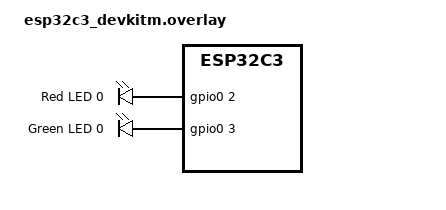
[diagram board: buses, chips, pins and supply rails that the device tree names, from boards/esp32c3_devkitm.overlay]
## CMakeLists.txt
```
# SPDX-License-Identifier: Apache-2.0

cmake_minimum_required(VERSION 3.20.0)

find_package(Zephyr REQUIRED HINTS $ENV{ZEPHYR_BASE})
project(ESP32_Zephyr_WebServer_LED_Control)

target_sources(app PRIVATE src/main.c)

zephyr_linker_sources(SECTIONS sections-rom.ld)
zephyr_linker_section(NAME http_resource_desc_http_service
                      KVMA RAM_REGION GROUP RODATA_REGION)

set(gen_dir ${ZEPHYR_BINARY_DIR}/include/generated/)
set(source_file_index src/root.html)
generate_inc_file_for_target(app ${source_file_index} ${gen_dir}/root.html.gz.inc)
```

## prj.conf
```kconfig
# Wi-Fi Configuration
CONFIG_WIFI=y

# Network Configuration
CONFIG_NET_CONFIG_AUTO_INIT=n
CONFIG_NET_CONNECTION_MANAGER=y
CONFIG_NET_DHCPV4=y
CONFIG_NET_DHCPV4_SERVER=y
CONFIG_NET_IF_MAX_IPV4_COUNT=2
CONFIG_NET_IF_MAX_IPV6_COUNT=2
CONFIG_NET_IPV4=y
CONFIG_NET_L2_ETHERNET=y
CONFIG_NET_L2_WIFI_MGMT=y
CONFIG_NET_MGMT=y
CONFIG_NET_MGMT_EVENT=y
CONFIG_NET_MGMT_EVENT_INFO=y
CONFIG_NET_MGMT_EVENT_QUEUE_SIZE=10
CONFIG_NET_MGMT_EVENT_STACK_SIZE=4096
CONFIG_NET_PKT_RX_COUNT=16
CONFIG_NET_PKT_TX_COUNT=16
CONFIG_NET_SOCKETS_SERVICE_STACK_SIZE=4096
CONFIG_NET_TCP=y
CONFIG_NET_UDP=y
CONFIG_NETWORKING=y

# LOG Configuration
CONFIG_NET_LOG=y
CONFIG_NET_DHCPV4_SERVER_LOG_LEVEL_DBG=y

# HTTP parser
CONFIG_HTTP_SERVER=y

# Enable GPIO
CONFIG_GPIO=y
```

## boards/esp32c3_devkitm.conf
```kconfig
CONFIG_WIFI_NM=y
CONFIG_WIFI_ESP32=y
CONFIG_ESP32_WIFI_STA_AUTO_DHCPV4=y
CONFIG_ESP32_WIFI_AP_STA_MODE=y
CONFIG_WIFI_NM_MAX_MANAGED_INTERFACES=2
CONFIG_ZVFS_EVENTFD_MAX=2

# apsta_mode configuration
CONFIG_WIFI_SAMPLE_AP_SSID="EmbeTronics"
CONFIG_WIFI_SAMPLE_AP_PSK="12345678"
CONFIG_WIFI_SAMPLE_SSID="SAMPLE_SSID"
CONFIG_WIFI_SAMPLE_PSK="SAMPLE_SSID"
CONFIG_WIFI_SAMPLE_DHCPV4_START=y
CONFIG_WIFI_SAMPLE_AP_IP_ADDRESS="192.168.4.1"
CONFIG_WIFI_SAMPLE_AP_NETMASK="255.255.255.0"

# stack size
CONFIG_SHELL_STACK_SIZE=6144
CONFIG_SYSTEM_WORKQUEUE_STACK_SIZE=2048
CONFIG_NET_MGMT_EVENT_STACK_SIZE=4608
CONFIG_NET_TCP_WORKQ_STACK_SIZE=2048
CONFIG_MAIN_STACK_SIZE=4096
CONFIG_IDLE_STACK_SIZE=1024
CONFIG_NET_MGMT_EVENT_QUEUE_SIZE=10
CONFIG_HEAP_MEM_POOL_SIZE=65535
```

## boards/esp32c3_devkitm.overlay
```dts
/ {
	aliases {
		redled = &redled;
		greenled = &greenled;
	};

	wifi_ap: wifi_ap {
		compatible = "espressif,esp32-wifi";
		status = "okay";
	};

	leds {
		compatible = "gpio-leds";

		redled: redled_0 {
			gpios = <&gpio0 2 GPIO_ACTIVE_HIGH>;
			label = "Red LED 0";
		};

		greenled: grrenled_0 {
			gpios = <&gpio0 3 GPIO_ACTIVE_HIGH>;
			label = "Green LED 0";
		};
	};
};
```

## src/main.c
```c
/*
 * Copyright (c) 2026 EmbeTronics
 *
 * SPDX-License-Identifier: Apache-2.0
 */

#include <zephyr/kernel.h>
#include <zephyr/logging/log.h>
#include <zephyr/net/wifi_mgmt.h>
#include <zephyr/net/dhcpv4_server.h>
#include <zephyr/net/http/service.h>
#include <zephyr/drivers/gpio.h>

LOG_MODULE_REGISTER(MAIN);

/* The devicetree node identifier for the "led0" alias. */
#define RED_NODE 	DT_ALIAS(redled)
#define GREEN_NODE 	DT_ALIAS(greenled)

static const struct gpio_dt_spec redled = GPIO_DT_SPEC_GET(RED_NODE, gpios);
static const struct gpio_dt_spec greenled = GPIO_DT_SPEC_GET(GREEN_NODE, gpios);

#define MACSTR "%02X:%02X:%02X:%02X:%02X:%02X"

#define NET_EVENT_WIFI_MASK                                                                        \
	(NET_EVENT_WIFI_CONNECT_RESULT | NET_EVENT_WIFI_DISCONNECT_RESULT |                        \
	 NET_EVENT_WIFI_AP_ENABLE_RESULT | NET_EVENT_WIFI_AP_DISABLE_RESULT |                      \
	 NET_EVENT_WIFI_AP_STA_CONNECTED | NET_EVENT_WIFI_AP_STA_DISCONNECTED)

static struct net_if *ap_iface;
static struct net_if *sta_iface;

static struct wifi_connect_req_params ap_config;
static struct wifi_connect_req_params sta_config;

static struct net_mgmt_event_callback cb;

/* Check necessary definitions */

BUILD_ASSERT(sizeof(CONFIG_WIFI_SAMPLE_AP_SSID) > 1,
	     "CONFIG_WIFI_SAMPLE_AP_SSID is empty. Please set it in conf file.");

BUILD_ASSERT(sizeof(CONFIG_WIFI_SAMPLE_SSID) > 1,
	     "CONFIG_WIFI_SAMPLE_SSID is empty. Please set it in conf file.");

#if WIFI_SAMPLE_DHCPV4_START
BUILD_ASSERT(sizeof(CONFIG_WIFI_SAMPLE_AP_IP_ADDRESS) > 1,
	     "CONFIG_WIFI_SAMPLE_AP_IP_ADDRESS is empty. Please set it in conf file.");

BUILD_ASSERT(sizeof(CONFIG_WIFI_SAMPLE_AP_NETMASK) > 1,
	     "CONFIG_WIFI_SAMPLE_AP_NETMASK is empty. Please set it in conf file.");

#endif

/********** HTTP Server ***********/

static uint8_t root_html_gz[] = {
#include "root.html.gz.inc"
};

static uint16_t http_service_port = 80;

static int default_handler(struct http_client_ctx *client, enum http_data_status status,
                   const struct http_request_ctx *request_ctx,
                   struct http_response_ctx *response_ctx, void *user_data)
{
	// LOG_INF("%s,%d, req %s", __func__, __LINE__, client->url_buffer);

	if(strstr(client->url_buffer,"GREEN_LED_ON"))
	{
		gpio_pin_set_dt(&greenled,1);
	}
	else if(strstr(client->url_buffer,"GREEN_LED_OFF"))
	{
		gpio_pin_set_dt(&greenled,0);
	}
	else if(strstr(client->url_buffer,"RED_LED_ON"))
	{
		gpio_pin_set_dt(&redled,1);
	}
	else if(strstr(client->url_buffer,"RED_LED_OFF"))
	{
		gpio_pin_set_dt(&redled,0);
	}

    if (status == HTTP_SERVER_DATA_FINAL) {
        response_ctx->status = HTTP_200_OK;
        response_ctx->body = root_html_gz;
        response_ctx->body_len = sizeof(root_html_gz) - 1;
        response_ctx->final_chunk = true;
    }

    return 0;
}

static struct http_resource_detail_dynamic default_detail = {
    .common = {
        .type = HTTP_RESOURCE_TYPE_DYNAMIC,
        .bitmask_of_supported_http_methods = BIT(HTTP_GET),
    },
    .cb = default_handler,
    .user_data = NULL,
};

HTTP_SERVICE_DEFINE(http_service, "0.0.0.0", &http_service_port, 1, 10, NULL, &default_detail, NULL);

static int root_get_handler(struct http_client_ctx *client, enum http_data_status status,
                   const struct http_request_ctx *request_ctx,
                   struct http_response_ctx *response_ctx, void *user_data)
{
    LOG_INF("%s,%d", __func__, __LINE__);

	response_ctx->status = HTTP_200_OK;
	response_ctx->body = root_html_gz;
	response_ctx->body_len = sizeof(root_html_gz);
	response_ctx->final_chunk = true;

    return 0;
}

struct http_resource_detail_static root_html_gz_resource_detail = {
    .common = {
        .type = HTTP_RESOURCE_TYPE_STATIC,
        .bitmask_of_supported_http_methods = BIT(HTTP_GET),
        // .content_encoding = "gzip",
    },
    .static_data = root_html_gz,
    .static_data_len = sizeof(root_html_gz),
};

HTTP_RESOURCE_DEFINE(root_html_gz_resource, http_service, "/",&root_html_gz_resource_detail);

/********** HTTP Server ***********/

static void wifi_event_handler(struct net_mgmt_event_callback *cb, uint64_t mgmt_event,
			       struct net_if *iface)
{
	switch (mgmt_event) {
	case NET_EVENT_WIFI_CONNECT_RESULT: {
		LOG_INF("Connected to %s", CONFIG_WIFI_SAMPLE_SSID);
		break;
	}
	case NET_EVENT_WIFI_DISCONNECT_RESULT: {
		LOG_INF("Disconnected from %s", CONFIG_WIFI_SAMPLE_SSID);
		break;
	}
	case NET_EVENT_WIFI_AP_ENABLE_RESULT: {
		LOG_INF("AP Mode is enabled. Waiting for station to connect");
		break;
	}
	case NET_EVENT_WIFI_AP_DISABLE_RESULT: {
		LOG_INF("AP Mode is disabled.");
		break;
	}
	case NET_EVENT_WIFI_AP_STA_CONNECTED: {
		struct wifi_ap_sta_info *sta_info = (struct wifi_ap_sta_info *)cb->info;

		LOG_INF("station: " MACSTR " joined ", sta_info->mac[0], sta_info->mac[1],
			sta_info->mac[2], sta_info->mac[3], sta_info->mac[4], sta_info->mac[5]);
		break;
	}
	case NET_EVENT_WIFI_AP_STA_DISCONNECTED: {
		struct wifi_ap_sta_info *sta_info = (struct wifi_ap_sta_info *)cb->info;

		LOG_INF("station: " MACSTR " leave ", sta_info->mac[0], sta_info->mac[1],
			sta_info->mac[2], sta_info->mac[3], sta_info->mac[4], sta_info->mac[5]);
		break;
	}
	default:
		break;
	}
}

#if CONFIG_WIFI_SAMPLE_DHCPV4_START
static void enable_dhcpv4_server(void)
{
	static struct net_in_addr addr;
	static struct net_in_addr netmaskAddr;

	if (net_addr_pton(NET_AF_INET, CONFIG_WIFI_SAMPLE_AP_IP_ADDRESS, &addr)) {
		LOG_ERR("Invalid address: %s", CONFIG_WIFI_SAMPLE_AP_IP_ADDRESS);
		return;
	}

	if (net_addr_pton(NET_AF_INET, CONFIG_WIFI_SAMPLE_AP_NETMASK, &netmaskAddr)) {
		LOG_ERR("Invalid netmask: %s", CONFIG_WIFI_SAMPLE_AP_NETMASK);
		return;
	}

	net_if_ipv4_set_gw(ap_iface, &addr);

	if (net_if_ipv4_addr_add(ap_iface, &addr, NET_ADDR_DHCP, 0) == NULL) {
		LOG_ERR("unable to set IP address for AP interface");
	}

	if (!net_if_ipv4_set_netmask_by_addr(ap_iface, &addr, &netmaskAddr)) {
		LOG_ERR("Unable to set netmask for AP interface: %s",
			 CONFIG_WIFI_SAMPLE_AP_NETMASK);
	}

	addr.s4_addr[3] += 10; /* Starting IPv4 address for DHCPv4 address pool. */

	if (net_dhcpv4_server_start(ap_iface, &addr) != 0) {
		LOG_ERR("DHCP server is not started for desired IP");
		return;
	}

	LOG_INF("DHCPv4 server started...\n");
}
#endif

static int enable_ap_mode(void)
{
	if (!ap_iface) {
		LOG_INF("AP: is not initialized");
		return -EIO;
	}

	LOG_INF("Turning on AP Mode");
	ap_config.ssid = (const uint8_t *)CONFIG_WIFI_SAMPLE_AP_SSID;
	ap_config.ssid_length = sizeof(CONFIG_WIFI_SAMPLE_AP_SSID) - 1;
	ap_config.psk = (const uint8_t *)CONFIG_WIFI_SAMPLE_AP_PSK;
	ap_config.psk_length = sizeof(CONFIG_WIFI_SAMPLE_AP_PSK) - 1;
	ap_config.channel = WIFI_CHANNEL_ANY;
	ap_config.band = WIFI_FREQ_BAND_2_4_GHZ;

	if (sizeof(CONFIG_WIFI_SAMPLE_AP_PSK) == 1) {
		ap_config.security = WIFI_SECURITY_TYPE_NONE;
	} else {

		ap_config.security = WIFI_SECURITY_TYPE_PSK;
	}

#if CONFIG_WIFI_SAMPLE_DHCPV4_START
	enable_dhcpv4_server();
#endif

	int ret = net_mgmt(NET_REQUEST_WIFI_AP_ENABLE, ap_iface, &ap_config,
			   sizeof(struct wifi_connect_req_params));
	if (ret) {
		LOG_ERR("NET_REQUEST_WIFI_AP_ENABLE failed, err: %d", ret);
	}

	return ret;
}

static int connect_to_wifi(void)
{
	if (!sta_iface) {
		LOG_INF("STA: interface no initialized");
		return -EIO;
	}

	sta_config.ssid = (const uint8_t *)CONFIG_WIFI_SAMPLE_SSID;
	sta_config.ssid_length = sizeof(CONFIG_WIFI_SAMPLE_SSID) - 1;
	sta_config.psk = (const uint8_t *)CONFIG_WIFI_SAMPLE_PSK;
	sta_config.psk_length = sizeof(CONFIG_WIFI_SAMPLE_PSK) - 1;
	sta_config.security = WIFI_SECURITY_TYPE_PSK;
	sta_config.channel = WIFI_CHANNEL_ANY;
	sta_config.band = WIFI_FREQ_BAND_2_4_GHZ;

	LOG_INF("Connecting to SSID: %s\n", sta_config.ssid);

	int ret = net_mgmt(NET_REQUEST_WIFI_CONNECT, sta_iface, &sta_config,
			   sizeof(struct wifi_connect_req_params));
	if (ret) {
		LOG_ERR("Unable to Connect to (%s)", CONFIG_WIFI_SAMPLE_SSID);
	}

	return ret;
}

int main(void)
{
	// k_sleep(K_SECONDS(5));

	/* Init LED GPIO Pins */
	int ret;

	if (!gpio_is_ready_dt(&redled)) {
		LOG_ERR("RED LED gpio not ready !!");
		return 0;
	}

	if (!gpio_is_ready_dt(&greenled)) {
		LOG_ERR("GREEN LED gpio not ready !!");
		return 0;
	}

	ret = gpio_pin_configure_dt(&redled, GPIO_OUTPUT_ACTIVE);
	if (ret < 0) {
		return 0;
	}

	ret = gpio_pin_configure_dt(&greenled, GPIO_OUTPUT_ACTIVE);
	if (ret < 0) {
		return 0;
	}

	// ret = gpio_pin_toggle_dt(&redled);
	// ret = gpio_pin_toggle_dt(&greenled);
	// k_sleep(K_SECONDS(2));
	// ret = gpio_pin_toggle_dt(&redled);
	// ret = gpio_pin_toggle_dt(&greenled);
	// k_sleep(K_SECONDS(2));
	// ret = gpio_pin_toggle_dt(&redled);
	// ret = gpio_pin_toggle_dt(&greenled);


	net_mgmt_init_event_callback(&cb, wifi_event_handler, NET_EVENT_WIFI_MASK);
	net_mgmt_add_event_callback(&cb);

	/* Get AP interface in AP-STA mode. */
	ap_iface = net_if_get_wifi_sap();

	/* Get STA interface in AP-STA mode. */
	sta_iface = net_if_get_wifi_sta();

	enable_ap_mode();
	connect_to_wifi();

	http_server_start();

	return 0;
}
```
